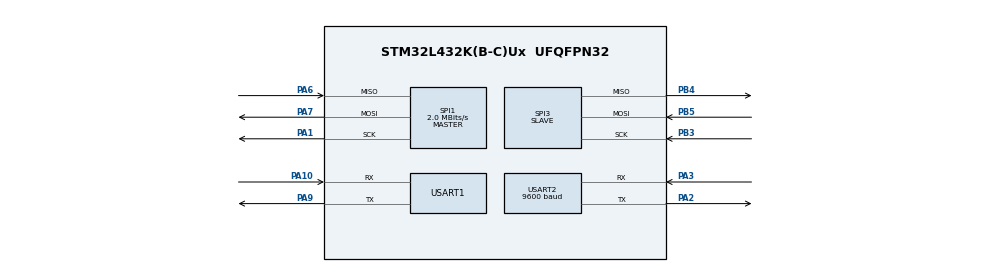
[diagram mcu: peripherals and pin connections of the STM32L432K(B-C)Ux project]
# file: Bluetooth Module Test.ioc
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Mcu.Family=STM32L4
Mcu.Name=STM32L432K(B-C)Ux
Mcu.Package=UFQFPN32
NVIC.PriorityGroup=NVIC_PRIORITYGROUP_4
PA1.Mode=Full_Duplex_Master
PA1.Signal=SPI1_SCK
PA10.Mode=Asynchronous
PA10.Signal=USART1_RX
PA13\ (JTMS-SWDIO).Mode=Serial_Wire
PA13\ (JTMS-SWDIO).Signal=SYS_JTMS-SWDIO
PA14\ (JTCK-SWCLK).Mode=Serial_Wire
PA14\ (JTCK-SWCLK).Signal=SYS_JTCK-SWCLK
PA2.Mode=Asynchronous
PA2.Signal=USART2_TX
PA3.Mode=Asynchronous
PA3.Signal=USART2_RX
PA6.Mode=Full_Duplex_Master
PA6.Signal=SPI1_MISO
PA7.Mode=Full_Duplex_Master
PA7.Signal=SPI1_MOSI
PA9.Mode=Asynchronous
PA9.Signal=USART1_TX
PB3\ (JTDO-TRACESWO).Mode=Full_Duplex_Slave
PB3\ (JTDO-TRACESWO).Signal=SPI3_SCK
PB4\ (NJTRST).Mode=Full_Duplex_Slave
PB4\ (NJTRST).Signal=SPI3_MISO
PB5.Mode=Full_Duplex_Slave
PB5.Signal=SPI3_MOSI
PC14-OSC32_IN\ (PC14).Mode=LSE-External-Oscillator
PC14-OSC32_IN\ (PC14).Signal=RCC_OSC32_IN
PC15-OSC32_OUT\ (PC15).Mode=LSE-External-Oscillator
PC15-OSC32_OUT\ (PC15).Signal=RCC_OSC32_OUT
ProjectManager.HeapSize=0x200
ProjectManager.StackSize=0x400
ProjectManager.TargetToolchain=MDK-ARM V5
RCC.HSE_VALUE=8000000
RCC.HSI48_VALUE=48000000
RCC.HSI_VALUE=16000000
RCC.MSI_VALUE=4000000
RCC.VCOOutputFreq_Value=32000000
SPI1.CalculateBaudRate=2.0 MBits/s
SPI1.DataSize=SPI_DATASIZE_8BIT
SPI1.Direction=SPI_DIRECTION_2LINES
SPI1.Mode=SPI_MODE_MASTER
SPI1.VirtualType=VM_MASTER
SPI3.DataSize=SPI_DATASIZE_8BIT
SPI3.Direction=SPI_DIRECTION_2LINES
SPI3.Mode=SPI_MODE_SLAVE
SPI3.VirtualType=VM_SLAVE
USART1.VirtualMode-Asynchronous=VM_ASYNC
USART2.BaudRate=9600
USART2.VirtualMode-Asynchronous=VM_ASYNC
board=custom

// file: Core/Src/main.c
/* USER CODE BEGIN Header */
/**
  ******************************************************************************
  * @file           : main.c
  * @brief          : Main program body
  ******************************************************************************
  * @attention
  *
  * <h2><center>&copy; Copyright (c) 2021 STMicroelectronics.
  * All rights reserved.</center></h2>
  *
  * This software component is licensed by ST under BSD 3-Clause license,
  * the "License"; You may not use this file except in compliance with the
  * License. You may obtain a copy of the License at:
  *                        opensource.org/licenses/BSD-3-Clause
  *
  ******************************************************************************
  */
/* USER CODE END Header */
#include "main.h"

SPI_HandleTypeDef hspi1;
SPI_HandleTypeDef hspi3;

UART_HandleTypeDef huart1;
UART_HandleTypeDef huart2;

void SystemClock_Config(void);
static void MX_GPIO_Init(void);
static void MX_USART1_UART_Init(void);
static void MX_USART2_UART_Init(void);
static void MX_SPI1_Init(void);
static void MX_SPI3_Init(void);

int main(void)
{

  /* MCU Configuration--------------------------------------------------------*/

  /* Reset of all peripherals, Initializes the Flash interface and the Systick. */
  HAL_Init();

  /* Configure the system clock */
  SystemClock_Config();

  /* Initialize all configured peripherals */
  MX_GPIO_Init();
  MX_USART1_UART_Init();
  MX_USART2_UART_Init();
  MX_SPI1_Init();
  MX_SPI3_Init();
  /* USER CODE BEGIN 2 */
	char data[3]={0};
	char data1[3]={0};
  /* USER CODE END 2 */

  /* Infinite loop */
  while (1)
  {

    /* USER CODE BEGIN 3 */
		HAL_UART_Receive(&huart1,(uint8_t*)data, sizeof(data), HAL_MAX_DELAY);

		HAL_SPI_Transmit(&hspi1, (uint8_t*)data, sizeof(data), 100);
		HAL_SPI_Receive(&hspi3, (uint8_t*)data1, sizeof(data1), 100);
		HAL_UART_Transmit(&huart2,(uint8_t*)data1, sizeof(data1), HAL_MAX_DELAY);
		HAL_Delay(1000);
  }
  /* USER CODE END 3 */
}

void SystemClock_Config(void)
{
  RCC_OscInitTypeDef RCC_OscInitStruct = {0};
  RCC_ClkInitTypeDef RCC_ClkInitStruct = {0};
  RCC_PeriphCLKInitTypeDef PeriphClkInit = {0};

  /** Configure LSE Drive Capability
  */
  HAL_PWR_EnableBkUpAccess();
  __HAL_RCC_LSEDRIVE_CONFIG(RCC_LSEDRIVE_LOW);
  /** Initializes the RCC Oscillators according to the specified parameters
  * in the RCC_OscInitTypeDef structure.
  */
  RCC_OscInitStruct.OscillatorType = RCC_OSCILLATORTYPE_LSE|RCC_OSCILLATORTYPE_MSI;
  RCC_OscInitStruct.LSEState = RCC_LSE_ON;
  RCC_OscInitStruct.MSIState = RCC_MSI_ON;
  RCC_OscInitStruct.MSICalibrationValue = 0;
  RCC_OscInitStruct.MSIClockRange = RCC_MSIRANGE_6;
  RCC_OscInitStruct.PLL.PLLState = RCC_PLL_NONE;
  if (HAL_RCC_OscConfig(&RCC_OscInitStruct) != HAL_OK)
  {
    Error_Handler();
  }
  /** Initializes the CPU, AHB and APB buses clocks
  */
  RCC_ClkInitStruct.ClockType = RCC_CLOCKTYPE_HCLK|RCC_CLOCKTYPE_SYSCLK
                              |RCC_CLOCKTYPE_PCLK1|RCC_CLOCKTYPE_PCLK2;
  RCC_ClkInitStruct.SYSCLKSource = RCC_SYSCLKSOURCE_MSI;
  RCC_ClkInitStruct.AHBCLKDivider = RCC_SYSCLK_DIV1;
  RCC_ClkInitStruct.APB1CLKDivider = RCC_HCLK_DIV1;
  RCC_ClkInitStruct.APB2CLKDivider = RCC_HCLK_DIV1;

  if (HAL_RCC_ClockConfig(&RCC_ClkInitStruct, FLASH_LATENCY_0) != HAL_OK)
  {
    Error_Handler();
  }
  PeriphClkInit.PeriphClockSelection = RCC_PERIPHCLK_USART1|RCC_PERIPHCLK_USART2;
  PeriphClkInit.Usart1ClockSelection = RCC_USART1CLKSOURCE_PCLK2;
  PeriphClkInit.Usart2ClockSelection = RCC_USART2CLKSOURCE_PCLK1;
  if (HAL_RCCEx_PeriphCLKConfig(&PeriphClkInit) != HAL_OK)
  {
    Error_Handler();
  }
  /** Configure the main internal regulator output voltage
  */
  if (HAL_PWREx_ControlVoltageScaling(PWR_REGULATOR_VOLTAGE_SCALE1) != HAL_OK)
  {
    Error_Handler();
  }
  /** Enable MSI Auto calibration
  */
  HAL_RCCEx_EnableMSIPLLMode();
}

static void MX_SPI1_Init(void)
{

  /* SPI1 parameter configuration*/
  hspi1.Instance = SPI1;
  hspi1.Init.Mode = SPI_MODE_MASTER;
  hspi1.Init.Direction = SPI_DIRECTION_2LINES;
  hspi1.Init.DataSize = SPI_DATASIZE_8BIT;
  hspi1.Init.CLKPolarity = SPI_POLARITY_LOW;
  hspi1.Init.CLKPhase = SPI_PHASE_1EDGE;
  hspi1.Init.NSS = SPI_NSS_SOFT;
  hspi1.Init.BaudRatePrescaler = SPI_BAUDRATEPRESCALER_2;
  hspi1.Init.FirstBit = SPI_FIRSTBIT_MSB;
  hspi1.Init.TIMode = SPI_TIMODE_DISABLE;
  hspi1.Init.CRCCalculation = SPI_CRCCALCULATION_DISABLE;
  hspi1.Init.CRCPolynomial = 7;
  hspi1.Init.CRCLength = SPI_CRC_LENGTH_DATASIZE;
  hspi1.Init.NSSPMode = SPI_NSS_PULSE_ENABLE;
  if (HAL_SPI_Init(&hspi1) != HAL_OK)
  {
    Error_Handler();
  }

}

static void MX_SPI3_Init(void)
{

  /* SPI3 parameter configuration*/
  hspi3.Instance = SPI3;
  hspi3.Init.Mode = SPI_MODE_SLAVE;
  hspi3.Init.Direction = SPI_DIRECTION_2LINES;
  hspi3.Init.DataSize = SPI_DATASIZE_8BIT;
  hspi3.Init.CLKPolarity = SPI_POLARITY_LOW;
  hspi3.Init.CLKPhase = SPI_PHASE_1EDGE;
  hspi3.Init.NSS = SPI_NSS_SOFT;
  hspi3.Init.FirstBit = SPI_FIRSTBIT_MSB;
  hspi3.Init.TIMode = SPI_TIMODE_DISABLE;
  hspi3.Init.CRCCalculation = SPI_CRCCALCULATION_DISABLE;
  hspi3.Init.CRCPolynomial = 7;
  hspi3.Init.CRCLength = SPI_CRC_LENGTH_DATASIZE;
  hspi3.Init.NSSPMode = SPI_NSS_PULSE_DISABLE;
  if (HAL_SPI_Init(&hspi3) != HAL_OK)
  {
    Error_Handler();
  }

}

static void MX_USART1_UART_Init(void)
{

  huart1.Instance = USART1;
  huart1.Init.BaudRate = 115200;
  huart1.Init.WordLength = UART_WORDLENGTH_8B;
  huart1.Init.StopBits = UART_STOPBITS_1;
  huart1.Init.Parity = UART_PARITY_NONE;
  huart1.Init.Mode = UART_MODE_TX_RX;
  huart1.Init.HwFlowCtl = UART_HWCONTROL_NONE;
  huart1.Init.OverSampling = UART_OVERSAMPLING_16;
  huart1.Init.OneBitSampling = UART_ONE_BIT_SAMPLE_DISABLE;
  huart1.AdvancedInit.AdvFeatureInit = UART_ADVFEATURE_NO_INIT;
  if (HAL_UART_Init(&huart1) != HAL_OK)
  {
    Error_Handler();
  }

}

static void MX_USART2_UART_Init(void)
{

  huart2.Instance = USART2;
  huart2.Init.BaudRate = 9600;
  huart2.Init.WordLength = UART_WORDLENGTH_8B;
  huart2.Init.StopBits = UART_STOPBITS_1;
  huart2.Init.Parity = UART_PARITY_NONE;
  huart2.Init.Mode = UART_MODE_TX_RX;
  huart2.Init.HwFlowCtl = UART_HWCONTROL_NONE;
  huart2.Init.OverSampling = UART_OVERSAMPLING_16;
  huart2.Init.OneBitSampling = UART_ONE_BIT_SAMPLE_DISABLE;
  huart2.AdvancedInit.AdvFeatureInit = UART_ADVFEATURE_NO_INIT;
  if (HAL_UART_Init(&huart2) != HAL_OK)
  {
    Error_Handler();
  }

}

static void MX_GPIO_Init(void)
{

  /* GPIO Ports Clock Enable */
  __HAL_RCC_GPIOC_CLK_ENABLE();
  __HAL_RCC_GPIOA_CLK_ENABLE();
  __HAL_RCC_GPIOB_CLK_ENABLE();

}

void Error_Handler(void)
{
  __disable_irq();
  while (1)
  {
  }
}

/************************ (C) COPYRIGHT STMicroelectronics *****END OF FILE****/
